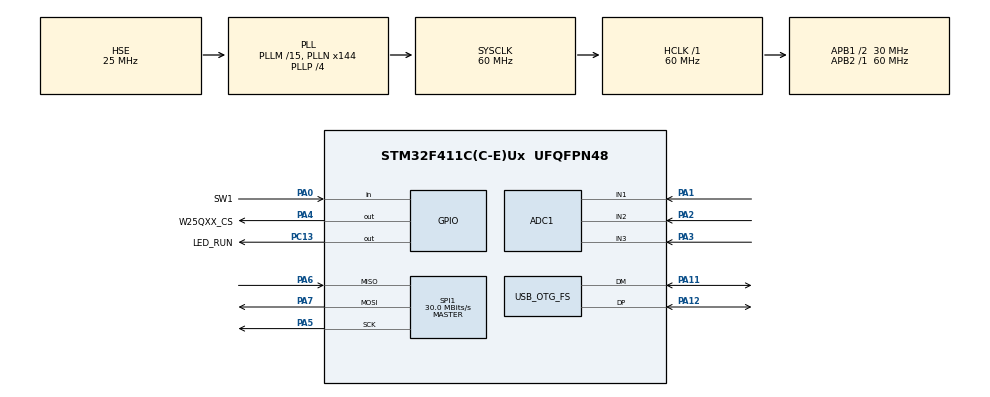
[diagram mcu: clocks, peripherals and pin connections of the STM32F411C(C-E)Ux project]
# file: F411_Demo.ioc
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ADC1.Channel-0\#ChannelRegularConversion=ADC_CHANNEL_1
ADC1.Channel-1\#ChannelRegularConversion=ADC_CHANNEL_2
ADC1.Channel-2\#ChannelRegularConversion=ADC_CHANNEL_3
ADC1.ContinuousConvMode=DISABLE
ADC1.DMAContinuousRequests=ENABLE
ADC1.DiscontinuousConvMode=DISABLE
ADC1.ExternalTrigConv=ADC_EXTERNALTRIGCONV_T3_TRGO
ADC1.NbrOfConversion=3
ADC1.NbrOfConversionFlag=1
ADC1.Rank-0\#ChannelRegularConversion=1
ADC1.Rank-1\#ChannelRegularConversion=2
ADC1.Rank-2\#ChannelRegularConversion=3
ADC1.SamplingTime-0\#ChannelRegularConversion=ADC_SAMPLETIME_3CYCLES
ADC1.SamplingTime-1\#ChannelRegularConversion=ADC_SAMPLETIME_3CYCLES
ADC1.SamplingTime-2\#ChannelRegularConversion=ADC_SAMPLETIME_3CYCLES
ADC1.ScanConvMode=ENABLE
ADC1.master=1
Dma.ADC1.0.Direction=DMA_PERIPH_TO_MEMORY
Dma.ADC1.0.FIFOMode=DMA_FIFOMODE_DISABLE
Dma.ADC1.0.Instance=DMA2_Stream0
Dma.ADC1.0.MemDataAlignment=DMA_MDATAALIGN_HALFWORD
Dma.ADC1.0.MemInc=DMA_MINC_ENABLE
Dma.ADC1.0.Mode=DMA_CIRCULAR
Dma.ADC1.0.PeriphDataAlignment=DMA_PDATAALIGN_HALFWORD
Dma.ADC1.0.PeriphInc=DMA_PINC_DISABLE
Dma.ADC1.0.Priority=DMA_PRIORITY_LOW
Dma.Request0=ADC1
Mcu.Family=STM32F4
Mcu.Name=STM32F411C(C-E)Ux
Mcu.Package=UFQFPN48
NVIC.ADC_IRQn=true\:2\:0\:true\:false\:true\:true\:true\:true
NVIC.DMA2_Stream0_IRQn=true\:1\:0\:true\:false\:true\:false\:true\:true
NVIC.FPU_IRQn=true\:0\:0\:false\:false\:true\:true\:false\:true
NVIC.OTG_FS_IRQn=true\:3\:0\:true\:false\:true\:false\:true\:true
NVIC.PriorityGroup=NVIC_PRIORITYGROUP_4
NVIC.RTC_WKUP_IRQn=true\:3\:0\:true\:false\:true\:true\:true\:true
NVIC.SPI1_IRQn=true\:3\:0\:true\:false\:true\:true\:true\:true
NVIC.TIM3_IRQn=true\:1\:0\:true\:false\:true\:true\:true\:true
PA0-WKUP.GPIO_Label=SW1
PA0-WKUP.GPIO_PuPd=GPIO_PULLUP
PA0-WKUP.Signal=GPIO_Input
PA1.Signal=ADCx_IN1
PA11.Mode=Device_Only
PA11.Signal=USB_OTG_FS_DM
PA12.Mode=Device_Only
PA12.Signal=USB_OTG_FS_DP
PA13.Mode=Serial_Wire
PA13.Signal=SYS_JTMS-SWDIO
PA14.Mode=Serial_Wire
PA14.Signal=SYS_JTCK-SWCLK
PA2.Signal=ADCx_IN2
PA3.Signal=ADCx_IN3
PA4.GPIO_Label=W25QXX_CS
PA4.Signal=GPIO_Output
PA5.Mode=Full_Duplex_Master
PA5.Signal=SPI1_SCK
PA6.Mode=Full_Duplex_Master
PA6.Signal=SPI1_MISO
PA7.Mode=Full_Duplex_Master
PA7.Signal=SPI1_MOSI
PC13-ANTI_TAMP.GPIO_Label=LED_RUN
PC13-ANTI_TAMP.Signal=GPIO_Output
PC14-OSC32_IN.Mode=LSE-External-Oscillator
PC14-OSC32_IN.Signal=RCC_OSC32_IN
PC15-OSC32_OUT.Mode=LSE-External-Oscillator
PC15-OSC32_OUT.Signal=RCC_OSC32_OUT
PH0\ -\ OSC_IN.Mode=HSE-External-Oscillator
PH0\ -\ OSC_IN.Signal=RCC_OSC_IN
PH1\ -\ OSC_OUT.Mode=HSE-External-Oscillator
PH1\ -\ OSC_OUT.Signal=RCC_OSC_OUT
ProjectManager.HeapSize=0x200
ProjectManager.StackSize=0x400
ProjectManager.TargetToolchain=MDK-ARM V5.32
RCC.48MHZClocksFreq_Value=48000000
RCC.AHBFreq_Value=60000000
RCC.APB1CLKDivider=RCC_HCLK_DIV2
RCC.APB1Freq_Value=30000000
RCC.APB1TimFreq_Value=60000000
RCC.APB2Freq_Value=60000000
RCC.APB2TimFreq_Value=60000000
RCC.CortexFreq_Value=60000000
RCC.HCLKFreq_Value=60000000
RCC.HSE_VALUE=25000000
RCC.HSI_VALUE=16000000
RCC.PLLM=15
RCC.PLLN=144
RCC.PLLP=RCC_PLLP_DIV4
RCC.PLLQ=5
RCC.RCC_RTC_Clock_Source=RCC_RTCCLKSOURCE_LSE
RCC.RCC_RTC_Clock_SourceVirtual=RCC_RTCCLKSOURCE_LSE
RCC.SYSCLKFreq_VALUE=60000000
RCC.SYSCLKSource=RCC_SYSCLKSOURCE_PLLCLK
RCC.VCOOutputFreq_Value=240000000
RTC.Format=RTC_FORMAT_BIN
RTC.HourFormat=RTC_HOURFORMAT_24
RTC.Hours=18
RTC.Minutes=59
RTC.Year=23
SH.ADCx_IN1.0=ADC1_IN1,IN1
SH.ADCx_IN2.0=ADC1_IN2,IN2
SH.ADCx_IN3.0=ADC1_IN3,IN3
SPI1.CalculateBaudRate=30.0 MBits/s
SPI1.Direction=SPI_DIRECTION_2LINES
SPI1.Mode=SPI_MODE_MASTER
SPI1.VirtualType=VM_MASTER
TIM3.AutoReloadPreload=TIM_AUTORELOAD_PRELOAD_DISABLE
TIM3.Period=10000-1
TIM3.Prescaler=3000-1
TIM3.TIM_MasterOutputTrigger=TIM_TRGO_UPDATE
USB_DEVICE.CLASS_NAME_FS=CDC
USB_DEVICE.USBD_DEBUG_LEVEL=0
USB_DEVICE.VirtualMode=Cdc
USB_DEVICE.VirtualModeFS=Cdc_FS
USB_OTG_FS.VirtualMode=Device_Only
VP_RTC_VS_RTC_Activate.Mode=RTC_Enabled
VP_RTC_VS_RTC_Calendar.Mode=RTC_Calendar
VP_RTC_VS_RTC_WakeUp_intern.Mode=WakeUp
VP_TIM3_VS_ClockSourceINT.Mode=Internal
VP_USB_DEVICE_VS_USB_DEVICE_CDC_FS.Mode=CDC_FS
board=custom

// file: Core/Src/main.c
/* USER CODE BEGIN Header */
/**
  ******************************************************************************
  * @file           : main.c
  * @brief          : Main program body
  ******************************************************************************
  * @attention
  *
  * Copyright (c) 2024 STMicroelectronics.
  * All rights reserved.
  *
  * This software is licensed under terms that can be found in the LICENSE file
  * in the root directory of this software component.
  * If no LICENSE file comes with this software, it is provided AS-IS.
  *
  ******************************************************************************
  */
/* USER CODE END Header */
#include "main.h"
#include "adc.h"
#include "dma.h"
#include "rtc.h"
#include "spi.h"
#include "tim.h"
#include "usb_device.h"
#include "gpio.h"

void SystemClock_Config(void);

int main(void)
{

  /* MCU Configuration--------------------------------------------------------*/

  /* Reset of all peripherals, Initializes the Flash interface and the Systick. */
  HAL_Init();

  /* Configure the system clock */
  SystemClock_Config();

  /* Initialize all configured peripherals */
  MX_GPIO_Init();
  MX_DMA_Init();
  MX_SPI1_Init();
  MX_USB_DEVICE_Init();
  MX_RTC_Init();
  MX_ADC1_Init();
  MX_TIM3_Init();
  /* USER CODE BEGIN 2 */
  Main_Init();
  Main_Loop();
  /* USER CODE END 2 */

  /* Infinite loop */
  while (1)
  {

  }
}

void SystemClock_Config(void)
{
  RCC_OscInitTypeDef RCC_OscInitStruct = {0};
  RCC_ClkInitTypeDef RCC_ClkInitStruct = {0};

  /** Configure the main internal regulator output voltage
  */
  __HAL_RCC_PWR_CLK_ENABLE();
  __HAL_PWR_VOLTAGESCALING_CONFIG(PWR_REGULATOR_VOLTAGE_SCALE1);

  /** Initializes the RCC Oscillators according to the specified parameters
  * in the RCC_OscInitTypeDef structure.
  */
  RCC_OscInitStruct.OscillatorType = RCC_OSCILLATORTYPE_HSE|RCC_OSCILLATORTYPE_LSE;
  RCC_OscInitStruct.HSEState = RCC_HSE_ON;
  RCC_OscInitStruct.LSEState = RCC_LSE_ON;
  RCC_OscInitStruct.PLL.PLLState = RCC_PLL_ON;
  RCC_OscInitStruct.PLL.PLLSource = RCC_PLLSOURCE_HSE;
  RCC_OscInitStruct.PLL.PLLM = 15;
  RCC_OscInitStruct.PLL.PLLN = 144;
  RCC_OscInitStruct.PLL.PLLP = RCC_PLLP_DIV4;
  RCC_OscInitStruct.PLL.PLLQ = 5;
  if (HAL_RCC_OscConfig(&RCC_OscInitStruct) != HAL_OK)
  {
    Error_Handler();
  }

  /** Initializes the CPU, AHB and APB buses clocks
  */
  RCC_ClkInitStruct.ClockType = RCC_CLOCKTYPE_HCLK|RCC_CLOCKTYPE_SYSCLK
                              |RCC_CLOCKTYPE_PCLK1|RCC_CLOCKTYPE_PCLK2;
  RCC_ClkInitStruct.SYSCLKSource = RCC_SYSCLKSOURCE_PLLCLK;
  RCC_ClkInitStruct.AHBCLKDivider = RCC_SYSCLK_DIV1;
  RCC_ClkInitStruct.APB1CLKDivider = RCC_HCLK_DIV2;
  RCC_ClkInitStruct.APB2CLKDivider = RCC_HCLK_DIV1;

  if (HAL_RCC_ClockConfig(&RCC_ClkInitStruct, FLASH_LATENCY_1) != HAL_OK)
  {
    Error_Handler();
  }
}

void Error_Handler(void)
{
  __disable_irq();
  while (1)
  {
  }
}
